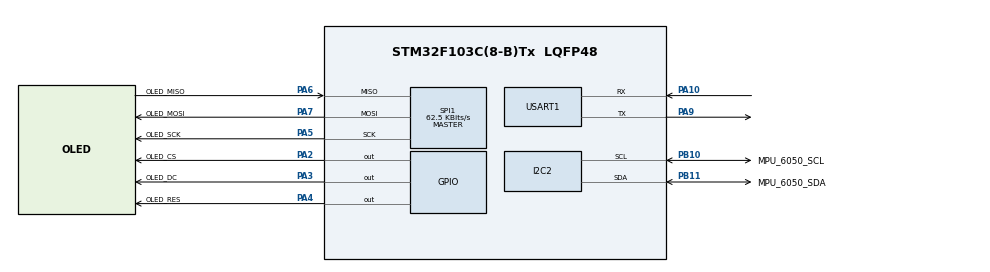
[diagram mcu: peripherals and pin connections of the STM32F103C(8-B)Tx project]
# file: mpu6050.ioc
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Mcu.Family=STM32F1
Mcu.Name=STM32F103C(8-B)Tx
Mcu.Package=LQFP48
NVIC.PriorityGroup=NVIC_PRIORITYGROUP_4
PA10.Mode=Asynchronous
PA10.Signal=USART1_RX
PA13.Mode=Serial_Wire
PA13.Signal=SYS_JTMS-SWDIO
PA14.Mode=Serial_Wire
PA14.Signal=SYS_JTCK-SWCLK
PA2.GPIO_Label=OLED_CS
PA2.Signal=GPIO_Output
PA3.GPIO_Label=OLED_DC
PA3.PinState=GPIO_PIN_SET
PA3.Signal=GPIO_Output
PA4.GPIO_Label=OLED_RES
PA4.PinState=GPIO_PIN_SET
PA4.Signal=GPIO_Output
PA5.GPIO_Label=OLED_SCK
PA5.Mode=Full_Duplex_Master
PA5.Signal=SPI1_SCK
PA6.GPIO_Label=OLED_MISO
PA6.Mode=Full_Duplex_Master
PA6.Signal=SPI1_MISO
PA7.GPIO_Label=OLED_MOSI
PA7.Mode=Full_Duplex_Master
PA7.Signal=SPI1_MOSI
PA9.Mode=Asynchronous
PA9.Signal=USART1_TX
PB10.GPIO_Label=MPU_6050_SCL
PB10.Mode=I2C
PB10.Signal=I2C2_SCL
PB11.GPIO_Label=MPU_6050_SDA
PB11.Mode=I2C
PB11.Signal=I2C2_SDA
PD0-OSC_IN.Mode=HSE-External-Oscillator
PD0-OSC_IN.Signal=RCC_OSC_IN
PD1-OSC_OUT.Mode=HSE-External-Oscillator
PD1-OSC_OUT.Signal=RCC_OSC_OUT
ProjectManager.HeapSize=0x200
ProjectManager.StackSize=0x400
ProjectManager.TargetToolchain=SW4STM32
RCC.APB1Freq_Value=8000000
RCC.APB2Freq_Value=8000000
SPI1.BaudRatePrescaler=SPI_BAUDRATEPRESCALER_128
SPI1.CalculateBaudRate=62.5 KBits/s
SPI1.Direction=SPI_DIRECTION_2LINES
SPI1.Mode=SPI_MODE_MASTER
SPI1.VirtualType=VM_MASTER
USART1.VirtualMode=VM_ASYNC
board=custom

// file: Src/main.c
/* USER CODE BEGIN Header */
/**
  ******************************************************************************
  * @file           : main.c
  * @brief          : Main program body
  ******************************************************************************
  * @attention
  *
  * <h2><center>&copy; Copyright (c) 2019 STMicroelectronics.
  * All rights reserved.</center></h2>
  *
  * This software component is licensed by ST under BSD 3-Clause license,
  * the "License"; You may not use this file except in compliance with the
  * License. You may obtain a copy of the License at:
  *                        opensource.org/licenses/BSD-3-Clause
  *
  ******************************************************************************
  */
/* USER CODE END Header */

#include "main.h"
#include "i2c.h"
#include "spi.h"
#include "usart.h"
#include "gpio.h"

/* USER CODE BEGIN Includes */
#include "mpu6050.h"
#include "oled.h"

/* USER CODE END Includes */

void SystemClock_Config(void);

int main(void)
{

  /* MCU Configuration--------------------------------------------------------*/

  /* Reset of all peripherals, Initializes the Flash interface and the Systick. */
  HAL_Init();

  /* Configure the system clock */
  SystemClock_Config();

  /* Initialize all configured peripherals */
  MX_GPIO_Init();
  MX_I2C2_Init();
  MX_SPI1_Init();
  MX_USART1_UART_Init();
  /* USER CODE BEGIN 2 */
  MPU_6050_Init();
  OLED_Init();
  char ch[]="中";
  short get[3];
  short tep;
  OLED_Clear();
  //OLED_ShowNum(0,4,123456789,9);
  OLED_ShowText(0,0,"换个IDE",24,24,0);

  //OLED_ShowText(0,4,"我我我我",16,16,0);

  /* USER CODE END 2 */

  /* Infinite loop */
  while (1)
  {

    /* USER CODE BEGIN 3 */
    MPU_Get_Gyroscope(&get[0],&get[1],&get[2]);
    tep=MPU_Get_Temperature();

      HAL_Delay(500);
      //OLED_Fill();
      //HAL_Delay(500);
      //OLED_CLEAN();
      //HAL_Delay(500);

    //MPU_6050_Read(0xD0+1,0x75,4,addr);
   // HAL_UART_Transmit(&huart1,get[0],8,20);
    //HAL_UART_Transmit(&huart1,get[1],8,20);
    //HAL_UART_Transmit(&huart1,get[2],8,20);
    HAL_Delay(500);

  }
  /* USER CODE END 3 */
}

void SystemClock_Config(void)
{
  RCC_OscInitTypeDef RCC_OscInitStruct = {0};
  RCC_ClkInitTypeDef RCC_ClkInitStruct = {0};

  /** Initializes the CPU, AHB and APB busses clocks
  */
  RCC_OscInitStruct.OscillatorType = RCC_OSCILLATORTYPE_HSI;
  RCC_OscInitStruct.HSIState = RCC_HSI_ON;
  RCC_OscInitStruct.HSICalibrationValue = RCC_HSICALIBRATION_DEFAULT;
  RCC_OscInitStruct.PLL.PLLState = RCC_PLL_NONE;
  if (HAL_RCC_OscConfig(&RCC_OscInitStruct) != HAL_OK)
  {
    Error_Handler();
  }
  /** Initializes the CPU, AHB and APB busses clocks
  */
  RCC_ClkInitStruct.ClockType = RCC_CLOCKTYPE_HCLK|RCC_CLOCKTYPE_SYSCLK
                              |RCC_CLOCKTYPE_PCLK1|RCC_CLOCKTYPE_PCLK2;
  RCC_ClkInitStruct.SYSCLKSource = RCC_SYSCLKSOURCE_HSI;
  RCC_ClkInitStruct.AHBCLKDivider = RCC_SYSCLK_DIV1;
  RCC_ClkInitStruct.APB1CLKDivider = RCC_HCLK_DIV1;
  RCC_ClkInitStruct.APB2CLKDivider = RCC_HCLK_DIV1;

  if (HAL_RCC_ClockConfig(&RCC_ClkInitStruct, FLASH_LATENCY_0) != HAL_OK)
  {
    Error_Handler();
  }
}

void Error_Handler(void)
{
}

/************************ (C) COPYRIGHT STMicroelectronics *****END OF FILE****/
